# MDR1986BE4 register map
Vendor: Milandr; File version: 1.0
CPU: CM0 r2p0, little endian, no MPU, no FPU, 2 interrupt priority bits
Registers are 32-bit, read-write, reset 0x0 unless marked. A register's access mark holds for its fields unless they carry their own. Offsets are from the block's base; [hi:lo] are bit positions; {n}, {i} and the like mark numbered series.

## MDR_EEPROM — Flash programm memory interfase controller registers
Base 0x40018000; register names take the prefix MDR_EEPROM_
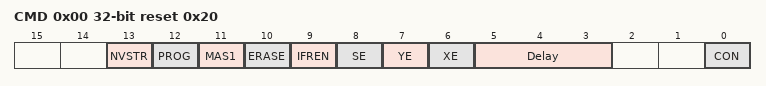
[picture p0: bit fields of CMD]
0x00 CMD reset 0x20 — EEPROM Command Register
  [13] NVSTR, [12] PROG, [11] MAS1, [10] ERASE, [9] IFREN, [8] SE, [7] YE, [6] XE, [5:3] Delay, [0] CON
0x04 ADR — EEPROM Address Register
0x08 DI — EEPROM Read Data Register
  [31:0] DATA
0x0C DO — EEPROM Write Data Register
  [31:0] DATA
0x10 KEY — EEPROM Key Register

## MDR_RST_CLK — RST_CLK
Base 0x40020000; register names take the prefix MDR_RST_CLK_
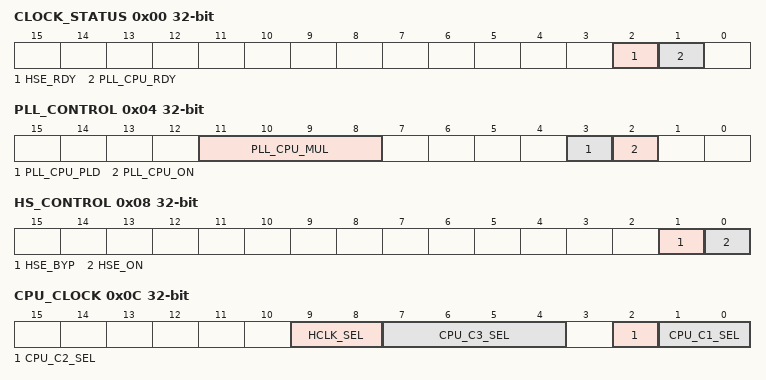
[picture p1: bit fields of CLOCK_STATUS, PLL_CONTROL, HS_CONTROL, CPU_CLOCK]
0x00 CLOCK_STATUS ro
  [2] HSE_RDY, [1] PLL_CPU_RDY
0x04 PLL_CONTROL
  [11:8] PLL_CPU_MUL, [3] PLL_CPU_PLD, [2] PLL_CPU_ON
0x08 HS_CONTROL
  [1] HSE_BYP, [0] HSE_ON
0x0C CPU_CLOCK
  [9:8] HCLK_SEL, [7:4] CPU_C3_SEL, [2] CPU_C2_SEL, [1:0] CPU_C1_SEL
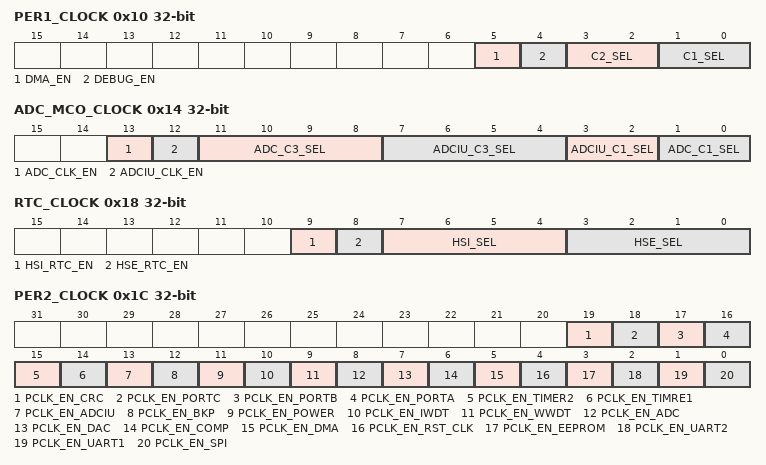
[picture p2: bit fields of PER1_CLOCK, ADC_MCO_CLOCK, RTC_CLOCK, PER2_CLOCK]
0x10 PER1_CLOCK
  [5] DMA_EN, [4] DEBUG_EN, [3:2] C2_SEL, [1:0] C1_SEL
0x14 ADC_MCO_CLOCK — ADC Clock Register
  [13] ADC_CLK_EN, [12] ADCIU_CLK_EN, [11:8] ADC_C3_SEL, [7:4] ADCIU_C3_SEL, [3:2] ADCIU_C1_SEL, [1:0] ADC_C1_SEL
0x18 RTC_CLOCK
  [9] HSI_RTC_EN, [8] HSE_RTC_EN, [7:4] HSI_SEL, [3:0] HSE_SEL
0x1C PER2_CLOCK — Peripheral Clock Enable Register
  [19] PCLK_EN_CRC, [18] PCLK_EN_PORTC, [17] PCLK_EN_PORTB, [16] PCLK_EN_PORTA, [15] PCLK_EN_TIMER2, [14] PCLK_EN_TIMRE1, [13] PCLK_EN_ADCIU, [12] PCLK_EN_BKP, [11] PCLK_EN_POWER, [10] PCLK_EN_IWDT, [9] PCLK_EN_WWDT, [8] PCLK_EN_ADC, [7] PCLK_EN_DAC, [6] PCLK_EN_COMP, [5] PCLK_EN_DMA, [4] PCLK_EN_RST_CLK, [3] PCLK_EN_EEPROM, [2] PCLK_EN_UART2, [1] PCLK_EN_UART1, [0] PCLK_EN_SPI
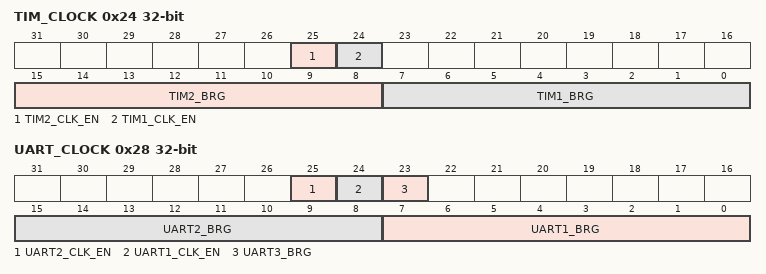
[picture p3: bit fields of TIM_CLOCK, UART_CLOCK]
0x24 TIM_CLOCK — Timer Clock Register
  [25] TIM2_CLK_EN, [24] TIM1_CLK_EN, [15:8] TIM2_BRG, [7:0] TIM1_BRG
0x28 UART_CLOCK
  [25] UART2_CLK_EN, [24] UART1_CLK_EN, [23] UART3_BRG, [15:8] UART2_BRG, [7:0] UART1_BRG

## MDR_DMA — DMA controller registers
Base 0x40028000; register names take the prefix MDR_DMA_
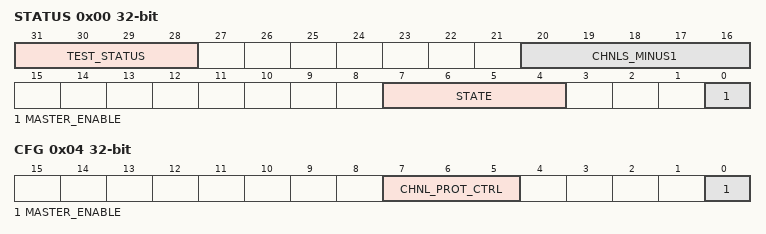
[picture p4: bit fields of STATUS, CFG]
0x00 STATUS — DMA Status Register
  [31:28] TEST_STATUS, [20:16] CHNLS_MINUS1, [7:4] STATE, [0] MASTER_ENABLE
0x04 CFG — DMA Configuration Register
  [7:5] CHNL_PROT_CTRL, [0] MASTER_ENABLE
0x08 CTRL_BASE_PTR
0x0C ALT_CTRL_BASE_PTR
0x10 WAITONREQ_STATUS
0x14 CHNL_SW_REQUEST
0x18 CHNL_USEBURST_SET
0x1C CHNL_USEBURST_CLR
0x20 CHNL_REQ_MASK_SET
0x24 CHNL_REQ_MASK_CLR
0x28 CHNL_ENABLE_SET
0x2C CHNL_ENABLE_CLR
0x30 CHNL_PRI_ALT_SET
0x34 CHNL_PRI_ALT_CLR
0x38 CHNL_PRIORITY_SET
0x3C CHNL_PRIORITY_CLR
0x4C ERR_CLR
  [0] ERR_CLR

## MDR_COMP — COMPARATOR
Base 0x40030000; register names take the prefix MDR_COMP_
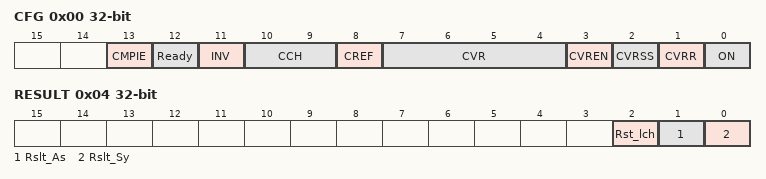
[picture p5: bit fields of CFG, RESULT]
0x00 CFG — COMP Configuration Register
  [13] CMPIE, [12] Ready, [11] INV, [10:9] CCH, [8] CREF, [7:4] CVR, [3] CVREN, [2] CVRSS, [1] CVRR, [0] ON
0x04 RESULT — COMP Result Register
  [2] Rst_lch, [1] Rslt_As, [0] Rslt_Sy
0x08 RESULT_LATCH — COMP Result Latch Register
  [0] Rst_lch

## MDR_DAC — DAC
Base 0x40038000; register names take the prefix MDR_DAC_
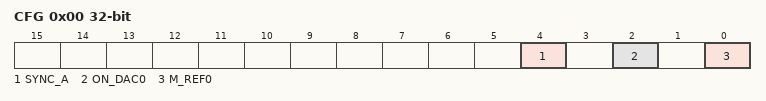
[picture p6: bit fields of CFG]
0x00 CFG — DAC Configuration Register
  [4] SYNC_A, [2] ON_DAC0, [0] M_REF0
0x04 DAC1_DATA
  [11:0] DAC0DATA

## MDR_ADC — ADC
Base 0x40040000; register names take the prefix MDR_ADC_
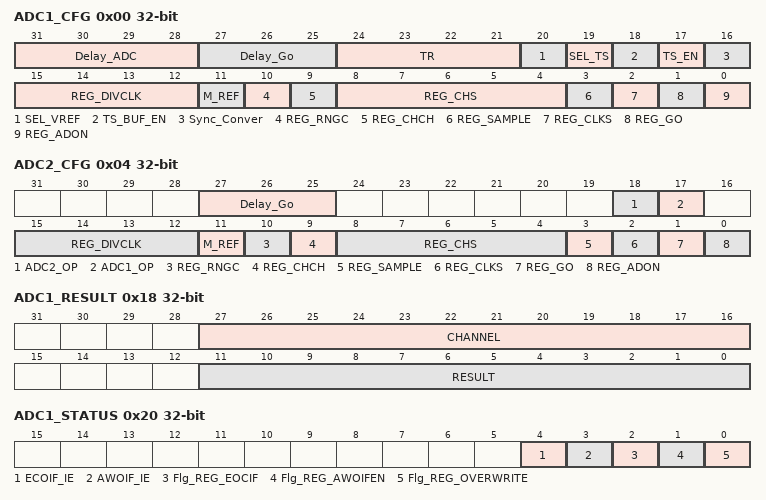
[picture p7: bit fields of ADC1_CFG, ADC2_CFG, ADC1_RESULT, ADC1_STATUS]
0x00 ADC1_CFG — ADC1 Configuration Register
  [31:28] Delay_ADC, [27:25] Delay_Go, [24:21] TR, [20] SEL_VREF, [19] SEL_TS, [18] TS_BUF_EN, [17] TS_EN, [16] Sync_Conver, [15:12] REG_DIVCLK, [11] M_REF, [10] REG_RNGC, [9] REG_CHCH, [8:4] REG_CHS, [3] REG_SAMPLE, [2] REG_CLKS, [1] REG_GO, [0] REG_ADON
0x04 ADC2_CFG — ADC2 Configuration Register
  [27:25] Delay_Go, [18] ADC2_OP, [17] ADC1_OP, [15:12] REG_DIVCLK, [11] M_REF, [10] REG_RNGC, [9] REG_CHCH, [8:4] REG_CHS, [3] REG_SAMPLE, [2] REG_CLKS, [1] REG_GO, [0] REG_ADON
0x08 ADC1_H_LEVEL — ADC1 High Level Register
  [11:0] REG_H_LEVEL
0x10 ADC1_L_LEVEL — ADC1 Low Level Register
  [11:0] REG_L_LEVEL
0x18 ADC1_RESULT
  [27:16] CHANNEL, [11:0] RESULT
0x20 ADC1_STATUS
  [4] ECOIF_IE, [3] AWOIF_IE, [2] Flg_REG_EOCIF, [1] Flg_REG_AWOIFEN, [0] Flg_REG_OVERWRITE
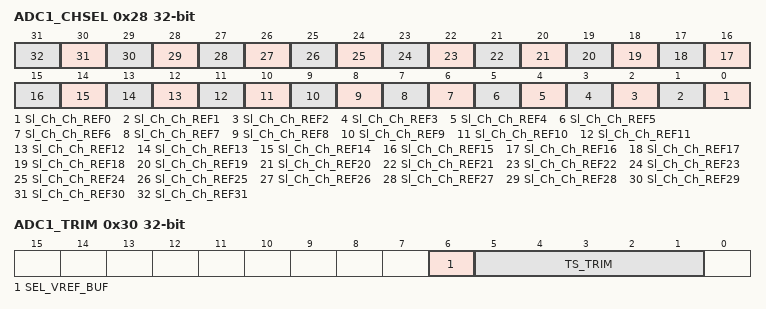
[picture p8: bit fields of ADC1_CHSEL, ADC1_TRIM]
0x28 ADC1_CHSEL — ADC1 Channel Selector Register
  [n] Sl_Ch_Ch_REF{n} (n=0..31)
0x30 ADC1_TRIM
  [6] SEL_VREF_BUF, [5:1] TS_TRIM
